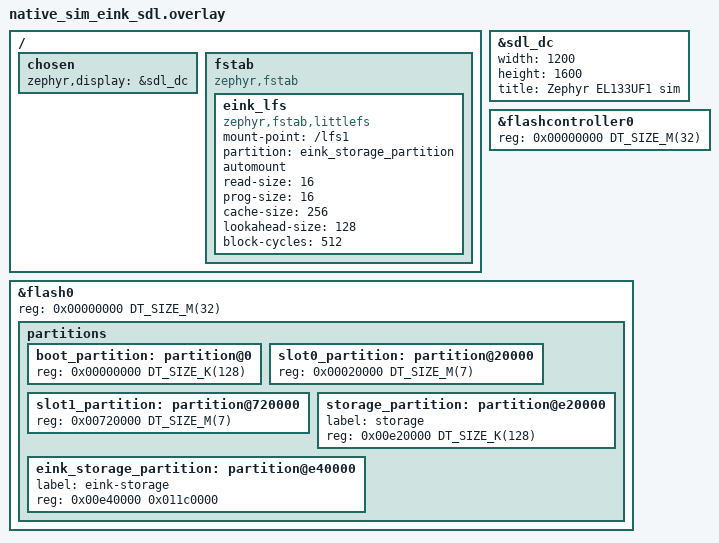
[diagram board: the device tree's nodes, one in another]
/*
 * Optional SDL window at 1200x1600.
 * Use with native_sim/native/64 + host amd64 SDL2
 * (default native_sim is -m32 and cannot link 64-bit SDL2).
 *
 * Model the proposed custom RT1170 board's 32 MiB XIP NOR:
 *   128 KiB MCUboot, 7 MiB slot A, 7 MiB slot B,
 *   128 KiB Mender NVS, and the remaining 17.75 MiB for e-ink LittleFS.
 */
/delete-node/ &boot_partition;
/delete-node/ &slot0_partition;
/delete-node/ &slot1_partition;
/delete-node/ &scratch_partition;
/delete-node/ &storage_partition;

&sdl_dc {
	status = "okay";
	width = <1200>;
	height = <1600>;
	title = "Zephyr EL133UF1 sim";
};

/ {
	chosen {
		zephyr,display = &sdl_dc;
	};

	fstab {
		compatible = "zephyr,fstab";

		eink_lfs: eink_lfs {
			compatible = "zephyr,fstab,littlefs";
			mount-point = "/lfs1";
			partition = <&eink_storage_partition>;
			automount;
			read-size = <16>;
			prog-size = <16>;
			cache-size = <256>;
			lookahead-size = <128>;
			block-cycles = <512>;
		};
	};
};

&flashcontroller0 {
	reg = <0x00000000 DT_SIZE_M(32)>;
};

&flash0 {
	reg = <0x00000000 DT_SIZE_M(32)>;

	partitions {
		boot_partition: partition@0 {
			reg = <0x00000000 DT_SIZE_K(128)>;
		};

		slot0_partition: partition@20000 {
			reg = <0x00020000 DT_SIZE_M(7)>;
		};

		slot1_partition: partition@720000 {
			reg = <0x00720000 DT_SIZE_M(7)>;
		};

		storage_partition: partition@e20000 {
			label = "storage";
			reg = <0x00e20000 DT_SIZE_K(128)>;
		};

		eink_storage_partition: partition@e40000 {
			label = "eink-storage";
			reg = <0x00e40000 0x011c0000>;
		};
	};
};
